# WBZ450 register map
Vendor: Microchip
Registers are 32-bit, read-write, reset 0x0 unless marked. A register's access mark holds for its fields unless they carry their own. Addresses are absolute, and some are shared; only a register's first bit layout is shown; [hi:lo] are bit positions; {n}, {i} and the like mark numbered series.

## HMATRIX
{0x42002480+8i} PRS{i}PRAS (i=0..15)
{0x42002484+8i} PRS{i}PRBS (i=0..15)

## TRNG
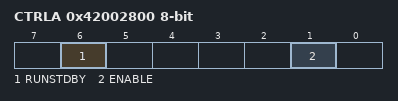
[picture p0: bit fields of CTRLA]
0x42002800 CTRLA 8-bit
  [6] RUNSTDBY — Run in Standby
  [1] ENABLE
0x42002804 EVCTRL 8-bit
  [0] DATARDYEO — Data Ready Event Output
0x42002808 INTENCLR 8-bit
  [0] DATARDY — Data Ready Interrupt Enable
0x42002809 INTENSET 8-bit
  [0] DATARDY — Data Ready Interrupt Enable
0x4200280A INTFLAG 8-bit
  [0] DATARDY — Data Ready Interrupt Flag
0x42002820 DATA ro
  [31:0] DATA — Output Data

## ICM
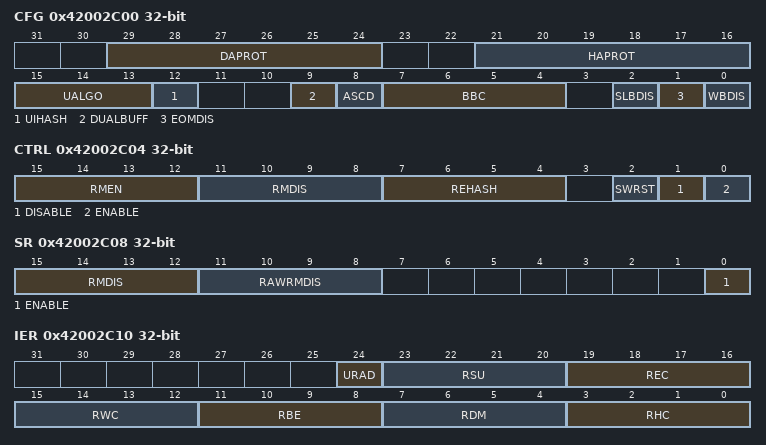
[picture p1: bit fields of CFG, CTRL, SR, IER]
0x42002C00 CFG
  [29:24] DAPROT — Region Descriptor Area Protection
  [21:16] HAPROT — Region Hash Area Protection
  [15:13] UALGO — User SHA Algorithm
    0=SHA1 (SHA1 Algorithm); 1=SHA256 (SHA256 Algorithm); 4=SHA224 (SHA224 Algorithm)
  [12] UIHASH — User Initial Hash Value
  [9] DUALBUFF — Dual Input Buffer
  [8] ASCD — Automatic Switch To Compare Digest
  [7:4] BBC — Bus Burden Control
  [2] SLBDIS — Secondary List Branching Disable
  [1] EOMDIS — End of Monitoring Disable
  [0] WBDIS — Write Back Disable
0x42002C04 CTRL wo reset not defined
  [15:12] RMEN — Region Monitoring Enable
  [11:8] RMDIS — Region Monitoring Disable
  [7:4] REHASH — Recompute Internal Hash
  [2] SWRST — Software Reset
  [1] DISABLE — ICM Disable Register
  [0] ENABLE — ICM Enable
0x42002C08 SR ro
  [15:12] RMDIS — Region Monitoring Disabled Status
  [11:8] RAWRMDIS — RAW Region Monitoring Disabled Status
  [0] ENABLE — ICM Controller Enable Register
0x42002C10 IER wo reset not defined
  [24] URAD — Undefined Register Access Detection Interrupt Enable
  [23:20] RSU — Region Status Updated Interrupt Disable
  [19:16] REC — Region End bit Condition Detected Interrupt Enable
  [15:12] RWC — Region Wrap Condition detected Interrupt Enable
  [11:8] RBE — Region Bus Error Interrupt Enable
  [7:4] RDM — Region Digest Mismatch Interrupt Enable
  [3:0] RHC — Region Hash Completed Interrupt Enable
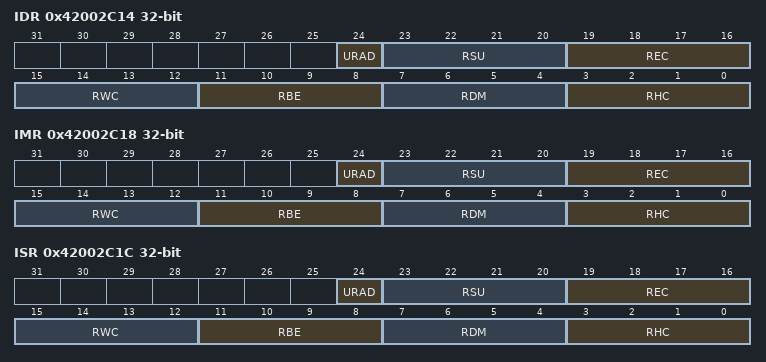
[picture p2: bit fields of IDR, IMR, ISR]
0x42002C14 IDR wo
  [24] URAD — Undefined Register Access Detection Interrupt Disable
  [23:20] RSU — Region Status Updated Interrupt Disable
  [19:16] REC — Region End bit Condition detected Interrupt Disable
  [15:12] RWC — Region Wrap Condition Detected Interrupt Disable
  [11:8] RBE — Region Bus Error Interrupt Disable
  [7:4] RDM — Region Digest Mismatch Interrupt Disable
  [3:0] RHC — Region Hash Completed Interrupt Disable
0x42002C18 IMR ro
  [24] URAD — Undefined Register Access Detection Interrupt Mask
  [23:20] RSU — Region Status Updated Interrupt Mask
  [19:16] REC — Region End bit Condition Detected Interrupt Mask
  [15:12] RWC — Region Wrap Condition Detected Interrupt Mask
  [11:8] RBE — Region Bus Error Interrupt Mask
  [7:4] RDM — Region Digest Mismatch Interrupt Mask
  [3:0] RHC — Region Hash Completed Interrupt Mask
0x42002C1C ISR ro
  [24] URAD — Undefined Register Access Detection Status
  [23:20] RSU — Region Status Updated Detected
  [19:16] REC — Region End bit Condition Detected
  [15:12] RWC — Region Wrap Condition Detected
  [11:8] RBE — Region Bus Error
  [7:4] RDM — Region Digest Mismatch
  [3:0] RHC — Region Hash Completed
0x42002C20 UASR ro
  [2:0] URAT — Undefined Register Access Trace
    0=UNSPEC_STRUCT_MEMBER (Unspecified structure member set to one detected when the descriptor is loaded); 1=CFG_MODIFIED (CFG modified during active monitoring); 2=DSCR_MODIFIED (DSCR modified during active monitoring); 3=HASH_MODIFIED (HASH modified during active monitoring); 4=READ_ACCESS (Write-only register read access)
0x42002C30 DSCR
  [31:6] DASA — Descriptor Area Start Address
0x42002C34 HASH
  [31:7] HASA — Hash Area Start Address
{0x42002C38+4i} UIHVAL{i} wo (i=0..7)
  [31:0] VAL — Initial Hash Value
